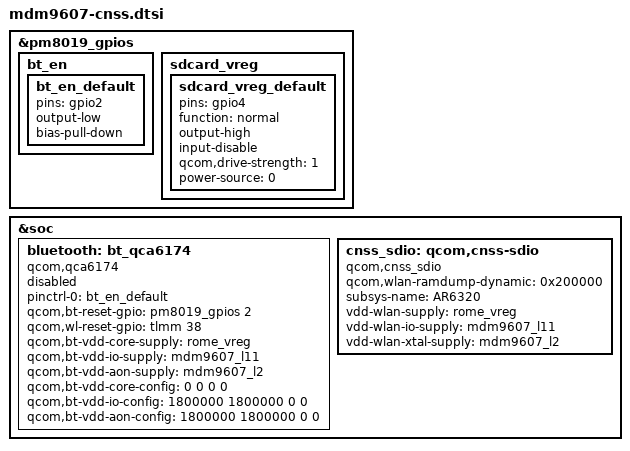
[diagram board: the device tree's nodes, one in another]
&pm8019_gpios {
	bt_en {
		bt_en_default: bt_en_default {
			pins = "gpio2";
			output-low;
			bias-pull-down;
		};
	};

	/* sdcard_ext_vreg GPIO 4 */
	sdcard_vreg {
		sdcard_vreg_default: sdcard_vreg_default {
			pins = "gpio4";
			function = "normal";
			output-high;
			input-disable;
			qcom,drive-strength = <1>;
			power-source = <0>;
		};
	};
};

&soc {
	bluetooth: bt_qca6174 {
		compatible = "qcom,qca6174";
		pinctrl-names = "default";
		pinctrl-0 = <&bt_en_default>;
		qcom,bt-reset-gpio = <&pm8019_gpios 2 0>;
		qcom,wl-reset-gpio = <&tlmm 38 0>;

		qcom,bt-vdd-core-supply = <&rome_vreg>;
		qcom,bt-vdd-io-supply   = <&mdm9607_l11>;
		qcom,bt-vdd-aon-supply  = <&mdm9607_l2>;

		qcom,bt-vdd-core-config = <0 0 0 0>;
		qcom,bt-vdd-io-config   = <1800000 1800000 0 0>;
		qcom,bt-vdd-aon-config  = <1800000 1800000 0 0>;
		status = "disabled";
	};

	cnss_sdio: qcom,cnss-sdio {
		compatible = "qcom,cnss_sdio";
		qcom,wlan-ramdump-dynamic = <0x200000>;
		subsys-name = "AR6320";
		vdd-wlan-supply = <&rome_vreg>;
		vdd-wlan-io-supply = <&mdm9607_l11>;
		vdd-wlan-xtal-supply = <&mdm9607_l2>;
	};
};
